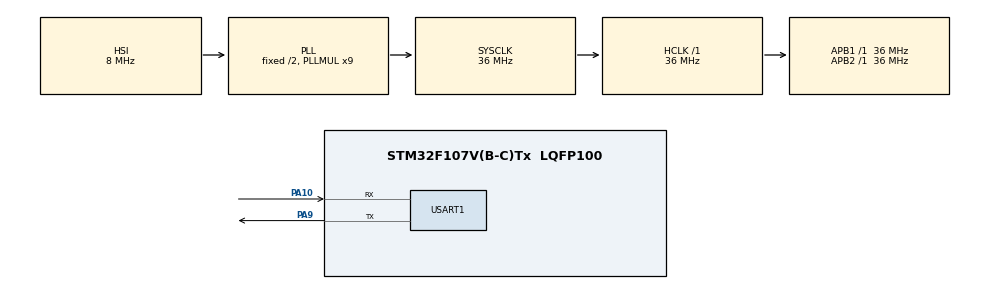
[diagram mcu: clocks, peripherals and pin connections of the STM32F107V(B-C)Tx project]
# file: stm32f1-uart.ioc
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Mcu.Family=STM32F1
RCC.PLLMUL=RCC_PLL_MUL9
RCC.APB2Freq_Value=36000000
PA10.Mode=Asynchronous
PA14.Mode=Serial_Wire
PA13.Mode=Serial_Wire
Mcu.Name=STM32F107V(B-C)Tx
RCC.SYSCLKFreq_VALUE=36000000
Mcu.Package=LQFP100
RCC.SYSCLKSource=RCC_SYSCLKSOURCE_PLLCLK
ProjectManager.StackSize=0x400
PA13.Signal=SYS_JTMS-SWDIO
USART1.VirtualMode=VM_ASYNC
PA9.Mode=Asynchronous
PA10.Signal=USART1_RX
PA14.Signal=SYS_JTCK-SWCLK
ProjectManager.HeapSize=0x200
ProjectManager.TargetToolchain=STM32CubeIDE
NVIC.PriorityGroup=NVIC_PRIORITYGROUP_4
RCC.HCLKFreq_Value=36000000
RCC.APB2TimFreq_Value=36000000
PA9.Signal=USART1_TX
RCC.APB1TimFreq_Value=36000000
RCC.USBFreq_Value=24000000
NVIC.USART1_IRQn=true\:0\:0\:false\:false\:true\:true\:true
RCC.APB1Freq_Value=36000000
RCC.AHBFreq_Value=36000000
board=custom

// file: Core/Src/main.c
/* USER CODE BEGIN Header */
/**
  ******************************************************************************
  * @file           : main.c
  * @brief          : Main program body
  ******************************************************************************
  * @attention
  *
  * <h2><center>&copy; Copyright (c) 2021 STMicroelectronics.
  * All rights reserved.</center></h2>
  *
  * This software component is licensed by ST under BSD 3-Clause license,
  * the "License"; You may not use this file except in compliance with the
  * License. You may obtain a copy of the License at:
  *                        opensource.org/licenses/BSD-3-Clause
  *
  ******************************************************************************
  */
/* USER CODE END Header */
#include "main.h"

/* USER CODE BEGIN Includes */
#include <stdio.h>
/* USER CODE END Includes */

/* USER CODE BEGIN PTD */
/* Private function prototypes -----------------------------------------------*/
#ifdef __GNUC__
 /* With GCC/RAISONANCE, small printf (option LD Linker->Libraries->Small printf
 set to 'Yes') calls __io_putchar() */
 #define PUTCHAR_PROTOTYPE int __io_putchar(int ch)
#else
 #define PUTCHAR_PROTOTYPE int fputc(int ch, FILE *f)
#endif /* __GNUC__ */
/* USER CODE END PTD */

UART_HandleTypeDef huart1;

void SystemClock_Config(void);
static void MX_GPIO_Init(void);
static void MX_USART1_UART_Init(void);

/* USER CODE BEGIN 0 */
uint8_t rx_data;
uint8_t tx_data[20]="STM32 Hello Man!!\r\n";

void HAL_UART_RxCpltCallback(UART_HandleTypeDef *huart){

	if(huart->Instance == USART1){
		HAL_UART_Transmit(&huart1,&rx_data,sizeof(rx_data), 100);
		HAL_UART_Receive_IT(&huart1, &rx_data, 1);
	}
}
/* USER CODE END 0 */

int main(void)
{

  /* MCU Configuration--------------------------------------------------------*/

  /* Reset of all peripherals, Initializes the Flash interface and the Systick. */
  HAL_Init();

  /* Configure the system clock */
  SystemClock_Config();

  /* Initialize all configured peripherals */
  MX_GPIO_Init();
  MX_USART1_UART_Init();
  /* USER CODE BEGIN 2 */
  HAL_UART_Transmit(&huart1,tx_data, sizeof(tx_data), 100);
  printf("STM32 hello from printf\r\n");
  HAL_UART_Receive_IT(&huart1, &rx_data, 1);
  /* USER CODE END 2 */

  /* Infinite loop */
  while (1)
  {

  }
}

void SystemClock_Config(void)
{
  RCC_OscInitTypeDef RCC_OscInitStruct = {0};
  RCC_ClkInitTypeDef RCC_ClkInitStruct = {0};

  /** Initializes the RCC Oscillators according to the specified parameters
  * in the RCC_OscInitTypeDef structure.
  */
  RCC_OscInitStruct.OscillatorType = RCC_OSCILLATORTYPE_HSI;
  RCC_OscInitStruct.HSIState = RCC_HSI_ON;
  RCC_OscInitStruct.HSICalibrationValue = RCC_HSICALIBRATION_DEFAULT;
  RCC_OscInitStruct.Prediv1Source = RCC_PREDIV1_SOURCE_HSE;
  RCC_OscInitStruct.PLL.PLLState = RCC_PLL_ON;
  RCC_OscInitStruct.PLL.PLLSource = RCC_PLLSOURCE_HSI_DIV2;
  RCC_OscInitStruct.PLL.PLLMUL = RCC_PLL_MUL9;
  RCC_OscInitStruct.PLL2.PLL2State = RCC_PLL_NONE;
  if (HAL_RCC_OscConfig(&RCC_OscInitStruct) != HAL_OK)
  {
    Error_Handler();
  }
  /** Initializes the CPU, AHB and APB buses clocks
  */
  RCC_ClkInitStruct.ClockType = RCC_CLOCKTYPE_HCLK|RCC_CLOCKTYPE_SYSCLK
                              |RCC_CLOCKTYPE_PCLK1|RCC_CLOCKTYPE_PCLK2;
  RCC_ClkInitStruct.SYSCLKSource = RCC_SYSCLKSOURCE_PLLCLK;
  RCC_ClkInitStruct.AHBCLKDivider = RCC_SYSCLK_DIV1;
  RCC_ClkInitStruct.APB1CLKDivider = RCC_HCLK_DIV1;
  RCC_ClkInitStruct.APB2CLKDivider = RCC_HCLK_DIV1;

  if (HAL_RCC_ClockConfig(&RCC_ClkInitStruct, FLASH_LATENCY_1) != HAL_OK)
  {
    Error_Handler();
  }
  /** Configure the Systick interrupt time
  */
  __HAL_RCC_PLLI2S_ENABLE();
}

static void MX_USART1_UART_Init(void)
{

  huart1.Instance = USART1;
  huart1.Init.BaudRate = 115200;
  huart1.Init.WordLength = UART_WORDLENGTH_8B;
  huart1.Init.StopBits = UART_STOPBITS_1;
  huart1.Init.Parity = UART_PARITY_NONE;
  huart1.Init.Mode = UART_MODE_TX_RX;
  huart1.Init.HwFlowCtl = UART_HWCONTROL_NONE;
  huart1.Init.OverSampling = UART_OVERSAMPLING_16;
  if (HAL_UART_Init(&huart1) != HAL_OK)
  {
    Error_Handler();
  }

}

static void MX_GPIO_Init(void)
{

  /* GPIO Ports Clock Enable */
  __HAL_RCC_GPIOA_CLK_ENABLE();

}

/* USER CODE BEGIN 4 */

/**
 * @brief Retargets the C library printf function to the USART.
 * @param None
 * @retval None
 */
PUTCHAR_PROTOTYPE
{
 /* Place your implementation of fputc here */
 /* e.g. write a character to the USART */
 HAL_UART_Transmit(&huart1, (uint8_t *)&ch, 1, 100);
 return ch;
}

/* USER CODE END 4 */

void Error_Handler(void)
{
  __disable_irq();
  while (1)
  {
  }
}

/************************ (C) COPYRIGHT STMicroelectronics *****END OF FILE****/
